# PIC32CM5164LE00048 device description
Architecture: CORTEX-M23; Family: PIC32CM; Series: PIC32CMLE00
Registers are 32-bit, read-write, reset 0x0 unless marked. A register's access mark holds for its fields unless they carry their own. Offsets are from the block's base; [hi:lo] are bit positions; lines under a group give offsets from that group; {n}, {i} and the like mark numbered series.

## DMAC_DESCRIPTOR — Direct Memory Access Controller
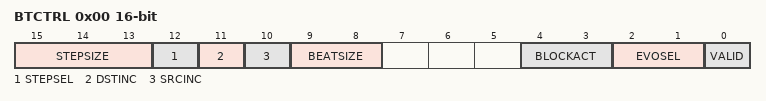
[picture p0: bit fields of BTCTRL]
0x00 BTCTRL 16-bit — Block Transfer Control
  [15:13] STEPSIZE — Address Increment Step Size
    0=Next ADDR = ADDR + (Beat Size in byte) * 1; 1=X2 (Next ADDR = ADDR + (Beat Size in byte) * 2); 2=X4 (Next ADDR = ADDR + (Beat Size in byte) * 4); 3=X8 (Next ADDR = ADDR + (Beat Size in byte) * 8); 4=X16 (Next ADDR = ADDR + (Beat Size in byte) * 16); 5=X32 (Next ADDR = ADDR + (Beat Size in byte) * 32); 6=X64 (Next ADDR = ADDR + (Beat Size in byte) * 64); 7=X128 (Next ADDR = ADDR + (Beat Size in byte) * 128)
  [12] STEPSEL — Step Selection
    0=DST (Step size settings apply to the destination address); 1=SRC (Step size settings apply to the source address)
  [11] DSTINC — Destination Address Increment Enable
  [10] SRCINC — Source Address Increment Enable
  [9:8] BEATSIZE
    0=BYTE (8-bit bus transfer); 1=HWORD (16-bit bus transfer); 2=WORD (32-bit bus transfer)
  [4:3] BLOCKACT — Block Action
    0=NOACT (Channel will be disabled if it is the last block transfer in the transaction); 1=INT (Channel will be disabled if it is the last block transfer in the transaction and block interrupt); 2=SUSPEND (Channel suspend operation is completed); 3=BOTH (Both channel suspend operation and block interrupt)
  [2:1] EVOSEL — Event Output Selection
    0=DISABLE (Event generation disabled); 1=BLOCK (Event strobe when block transfer complete); 3=BEAT (Event strobe when beat transfer complete)
  [0] VALID — Descriptor Valid
0x02 BTCNT 16-bit reset not defined — Block Transfer Count
0x04 SRCADDR reset not defined — Block Transfer Source Address
  [31:0] SRCADDR — Transfer Source Address
0x08 DSTADDR reset not defined — Block Transfer Destination Address
  [31:0] DSTADDR — Transfer Destination Address
0x0C DESCADDR reset not defined — Next Descriptor Address

## DWT — Data Watchpoint and Trace
Instances: DWT 0xE0001000
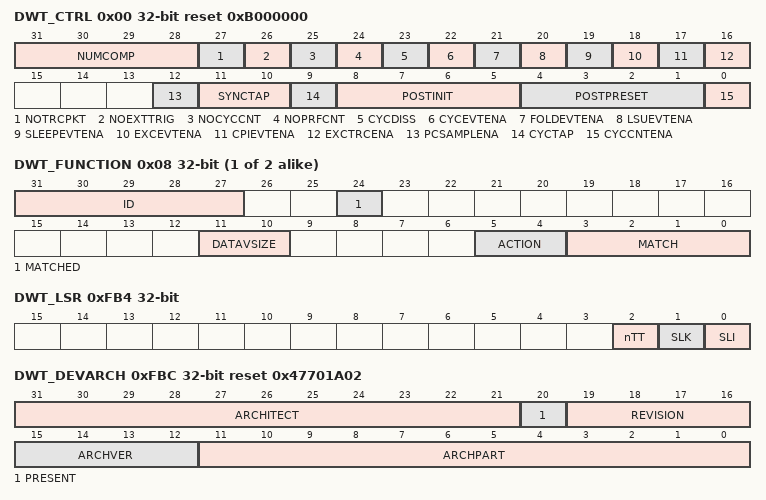
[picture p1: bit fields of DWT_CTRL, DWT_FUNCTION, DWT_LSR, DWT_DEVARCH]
0x00 DWT_CTRL reset 0xB000000 — DWT Control Register
  [31:28] NUMCOMP — Number of comparators
  [27] NOTRCPKT — No trace packets
  [26] NOEXTTRIG — No external triggers
  [25] NOCYCCNT — No cycle count
  [24] NOPRFCNT — No profile counters
  [23] CYCDISS — Cycle counter disabled secure
  [22] CYCEVTENA — Cycle event enable
  [21] FOLDEVTENA — Fold event enable
  [20] LSUEVTENA — LSU event enable
  [19] SLEEPEVTENA — Sleep event enable
  [18] EXCEVTENA — Exception event enable
  [17] CPIEVTENA — CPI event enable
  [16] EXCTRCENA — Exception trace enable
  [12] PCSAMPLENA — PC sample enable
  [11:10] SYNCTAP — Synchronization tap
  [9] CYCTAP — Cycle count tap
  [8:5] POSTINIT — POSTCNT initial
  [4:1] POSTPRESET — POSTCNT preset
  [0] CYCCNTENA — CYCCNT enable
0x1C DWT_PCSR ro reset not defined — DWT Program Counter Sample Register
  [31:0] EIASAMPLE — Executed instruction address sample
{0x20+0x10*i} COMPARATOR[{i}] (i=0..1) group
  0x00 DWT_COMP reset not defined — DWT Comparator Register n
    [31:0] VALUE — Cycle/PC/data value or data address
  0x08 DWT_FUNCTION reset not defined — DWT Function Register x
    [31:27] ID — Identify capability
    [24] MATCHED — Comparator matched
    [11:10] DATAVSIZE — Data value size
    [5:4] ACTION — Action on match
    [3:0] MATCH — Match type
0xFB0 DWT_LAR wo reset not defined — DWT Software Lock Access Register
  [31:0] KEY — Lock access control
    0xC5ACCE55=UNLOCK (Unlock key value)
0xFB4 DWT_LSR ro reset not defined — DWT Software Lock Status Register
  [2] nTT — Not thirty-two bit
  [1] SLK — Software Lock status
  [0] SLI — Software Lock implemented
0xFBC DWT_DEVARCH ro reset 0x47701A02 — DWT Device Architecture Register
  [31:21] ARCHITECT
  [20] PRESENT — DEVARCH Present
  [19:16] REVISION
  [15:12] ARCHVER — Architecture Version
  [11:0] ARCHPART — Architecture Part
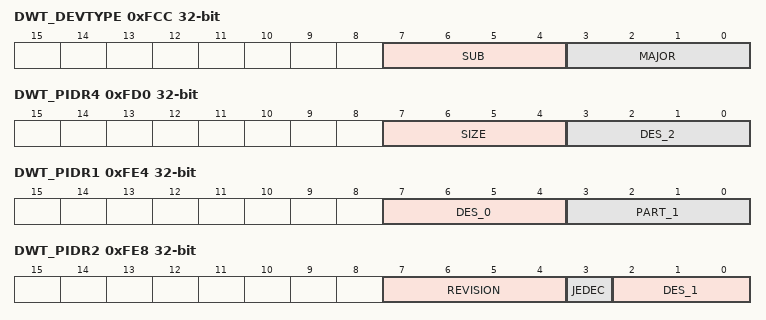
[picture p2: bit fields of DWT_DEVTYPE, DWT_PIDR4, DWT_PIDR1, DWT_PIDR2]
0xFCC DWT_DEVTYPE ro — DWT Device Type Register
  [7:4] SUB — Sub-type
  [3:0] MAJOR — Major type
0xFD0 DWT_PIDR4 ro reset not defined — DWT Peripheral Identification Register 4
  [7:4] SIZE — 4KB count
  [3:0] DES_2 — JEP106 continuation code
{0xFC0+4i} DWT_PIDR{i} ro (i=5..7) — DWT Peripheral Identification Register {i}
0xFE0 DWT_PIDR0 ro reset not defined — DWT Peripheral Identification Register 0
  [7:0] PART_0 — Part number bits[7:0]
0xFE4 DWT_PIDR1 ro reset not defined — DWT Peripheral Identification Register 1
  [7:4] DES_0 — JEP106 identification code bits [3:0]
  [3:0] PART_1 — Part number bits[11:8]
0xFE8 DWT_PIDR2 ro reset not defined — DWT Peripheral Identification Register 2
  [7:4] REVISION — Component revision
  [3] JEDEC — JEDEC assignee value is used
  [2:0] DES_1 — JEP106 identification code bits[6:4]
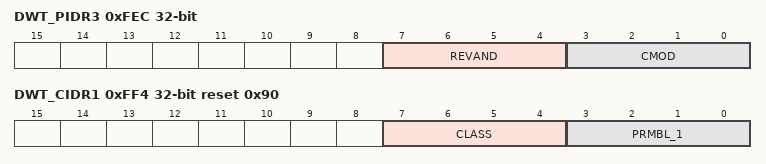
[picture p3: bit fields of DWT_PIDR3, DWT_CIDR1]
0xFEC DWT_PIDR3 ro reset not defined — DWT Peripheral Identification Register 3
  [7:4] REVAND
  [3:0] CMOD — Customer Modified
0xFF0 DWT_CIDR0 ro reset 0xD — DWT Component Identification Register 0
  [7:0] PRMBL_0 — CoreSight component identification preamble
0xFF4 DWT_CIDR1 ro reset 0x90 — DWT Component Identification Register 1
  [7:4] CLASS — CoreSight component class
  [3:0] PRMBL_1 — CoreSight component identification preamble
0xFF8 DWT_CIDR2 ro reset 0x5 — DWT Component Identification Register 2
  [7:0] PRMBL_2 — CoreSight component identification preamble
0xFFC DWT_CIDR3 ro reset 0xB1 — DWT Component Identification Register 3
  [7:0] PRMBL_3 — CoreSight component identification preamble

## Notices in the file
Copyright (c) 2019 Microchip Technology Inc.
SPDX-License-Identifier: Apache-2.0
Licensed under the Apache License, Version 2.0 (the "License");
you may not use this file except in compliance with the License.
You may obtain a copy of the License at
http://www.apache.org/licenses/LICENSE-2.0
Unless required by applicable law or agreed to in writing, software
distributed under the License is distributed on an "AS IS" BASIS,
WITHOUT WARRANTIES OR CONDITIONS OF ANY KIND, either express or implied.
See the License for the specific language governing permissions and
limitations under the License.
